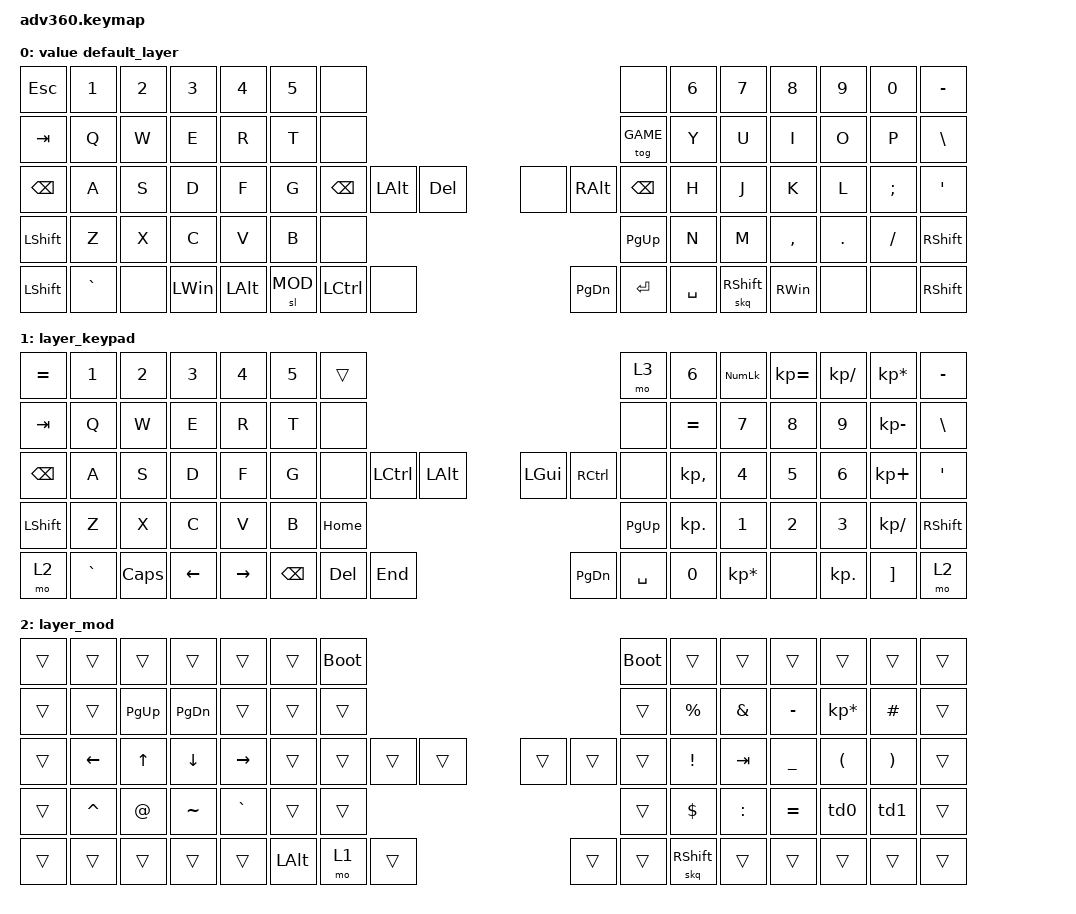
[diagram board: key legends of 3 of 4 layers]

/*
 * Copyright (c) 2020 The ZMK Contributors
 *
 * SPDX-License-Identifier: MIT
 */


/* THIS FILE WAS GENERATED!
 *
 * This file was generated automatically. You may or may not want to
 * edit it directly.
 */

#include <behaviors.dtsi>
#include <dt-bindings/zmk/keys.h>

#define MOD 2
#define GAME 3


// &mo doc: 
// https://zmk.dev/docs/behaviors/layers

// &sk {
//   release-after-ms = <2000>;
//   quick-release;
//   /delete-property/ ignore-modifiers;
// };

&sl {
  release-after-ms = <200>;
};

/ {
  behaviors {
    #include "macros.dtsi"

    hm: homerow_mods {
        compatible = "zmk,behavior-hold-tap";
        label = "HOMEROW_MODS";
        #binding-cells = <2>;
        tapping-term-ms = <200>;
        quick_tap_ms = <175>;
        flavor = "tap-preferred";
        bindings = <&kp>, <&kp>;
    };

    td0: tap_dance_0 {
        compatible = "zmk,behavior-tap-dance";
        label = "TAP_DANCE_0";
        #binding-cells = <0>;
        tapping-term-ms = <200>;
        bindings = <&kp LEFT_BRACE>, <&kp LEFT_BRACKET>;
    };

    td1: tap_dance_1 {
        compatible = "zmk,behavior-tap-dance";
        label = "TAP_DANCE_1";
        #binding-cells = <0>;
        tapping-term-ms = <200>;
        bindings = <&kp RIGHT_BRACE>, <&kp RIGHT_BRACKET>;
    };

    skq: sticky_key_quick_release {
        compatible = "zmk,behavior-sticky-key";
        label = "STICKY_KEY_QUICK_RELEASE";
        bindings = <&kp>;
        release-after-ms = <800>;
        quick-release;
        ignore-modifiers;
    };
  };

    keymap {
        compatible = "zmk,keymap";


value         default_layer {
            bindings = <
        &kp ESC     &kp N1  &kp N2    &kp N3    &kp N4  &kp N5            &none                                                                &none  &kp N6    &kp N7         &kp N8   &kp N9    &kp N0        &kp MINUS
        &kp TAB      &kp Q   &kp W     &kp E     &kp R   &kp T            &none                                                               &tog GAME   &kp Y     &kp U          &kp I    &kp O     &kp P         &kp BSLH
  &kp BACKSPACE      &kp A   &kp S     &kp D     &kp F   &kp G            &kp BACKSPACE   &kp LALT  &kp DEL                      &none   &kp RALT      &kp BACKSPACE   &kp H     &kp J          &kp K    &kp L  &kp SEMI          &kp SQT
      &kp LSHFT      &kp Z   &kp X     &kp C     &kp V   &kp B                                &none                  &kp PG_UP                         &kp N     &kp M      &kp COMMA  &kp DOT  &kp FSLH        &kp RSHFT
 &kp LEFT_SHIFT  &kp GRAVE   &none  &kp LWIN  &kp LALT                    &sl MOD  &kp LCTRL    &none                  &kp PG_DN  &kp ENTER  &kp SPACE          &skq RSHIFT  &kp RIGHT_WIN    &none     &none  &kp RIGHT_SHIFT
            >;
        };

        layer_keypad {
            bindings = <
 &kp EQUAL     &kp N1    &kp N2    &kp N3     &kp N4  &kp N5              &trans                                                                 &mo 3        &kp N6       &kp KP_NUM  &kp KP_EQUAL  &kp KP_DIVIDE  &kp KP_MULTIPLY  &kp MINUS
   &kp TAB      &kp Q     &kp W     &kp E      &kp R   &kp T               &none                                                                 &none     &kp EQUAL        &kp N7     &kp N8      &kp N9     &kp KP_MINUS   &kp BSLH
   &kp BACKSPACE &kp A     &kp S     &kp D      &kp F   &kp G               &none  &kp LCTRL  &kp LALT                   &kp LGUI  &kp RCTRL      &none  &kp KP_COMMA        &kp N4     &kp N5      &kp N6      &kp KP_PLUS    &kp SQT
 &kp LSHFT      &kp Z     &kp X     &kp C      &kp V   &kp B                                 &kp HOME                  &kp PG_UP                          &kp KP_DOT        &kp N1     &kp N2      &kp N3    &kp KP_DIVIDE  &kp RSHFT
     &mo 2  &kp GRAVE  &kp CAPS  &kp LEFT  &kp RIGHT                    &kp BSPC    &kp DEL   &kp END                  &kp PG_DN  &kp SPACE  &kp N0                &kp KP_MULTIPLY         &none     &kp KP_DOT         &kp RBKT      &mo 2
            >;
        };

        layer_mod {
            bindings = <
 &trans          &trans        &trans          &trans           &trans  &trans            &bootloader                                                  &bootloader           &trans         &trans          &trans                &trans                 &trans  &trans
 &trans          &trans     &kp PG_UP       &kp PG_DN           &trans  &trans            &trans                                                       &trans      &kp PERCENT  &kp AMPERSAND       &kp MINUS       &kp KP_MULTIPLY              &kp POUND  &trans
 &trans  &kp LEFT_ARROW  &kp UP_ARROW  &kp DOWN_ARROW  &kp RIGHT_ARROW  &trans            &trans  &trans    &trans                  &trans  &trans       &trans  &kp EXCLAMATION        &kp TAB  &kp UNDERSCORE  &kp LEFT_PARENTHESIS  &kp RIGHT_PARENTHESIS  &trans
 &trans       &kp CARET   &kp AT_SIGN       &kp TILDE        &kp GRAVE  &trans                              &trans                  &trans                            &kp DOLLAR      &kp COLON       &kp EQUAL        &td0        &td1  &trans
 &trans          &trans        &trans          &trans           &trans                    &kp LALT   &mo 1  &trans                  &trans  &trans   &skq RSHIFT                          &trans          &trans                &trans                 &trans  &trans
            >;
        };

        layer_game {
            bindings = <
 &trans     &trans    &trans    &trans    &trans    &trans    &trans                                                      &trans     &trans     &trans    &trans   &trans   &trans   &trans
 &trans     &trans    &trans    &trans    &trans    &trans    &trans                                                      &tog GAME  &trans     &trans    &trans   &trans   &trans   &trans
 &kp LCTRL  &trans    &trans    &trans    &trans    &trans    &trans     &trans  &trans                  &trans  &trans   &trans     &trans     &trans    &trans   &trans   &trans   &trans
 &trans     &trans    &trans    &trans    &trans    &trans                       &trans                  &trans                      &trans     &trans    &trans   &trans   &trans   &trans
 &trans     &trans    &trans    &trans    &trans              &kp SPACE  &trans  &trans                  &trans  &trans   &trans     &trans     &trans    &trans   &trans   &trans   &trans
            >;
        };

    };
};
